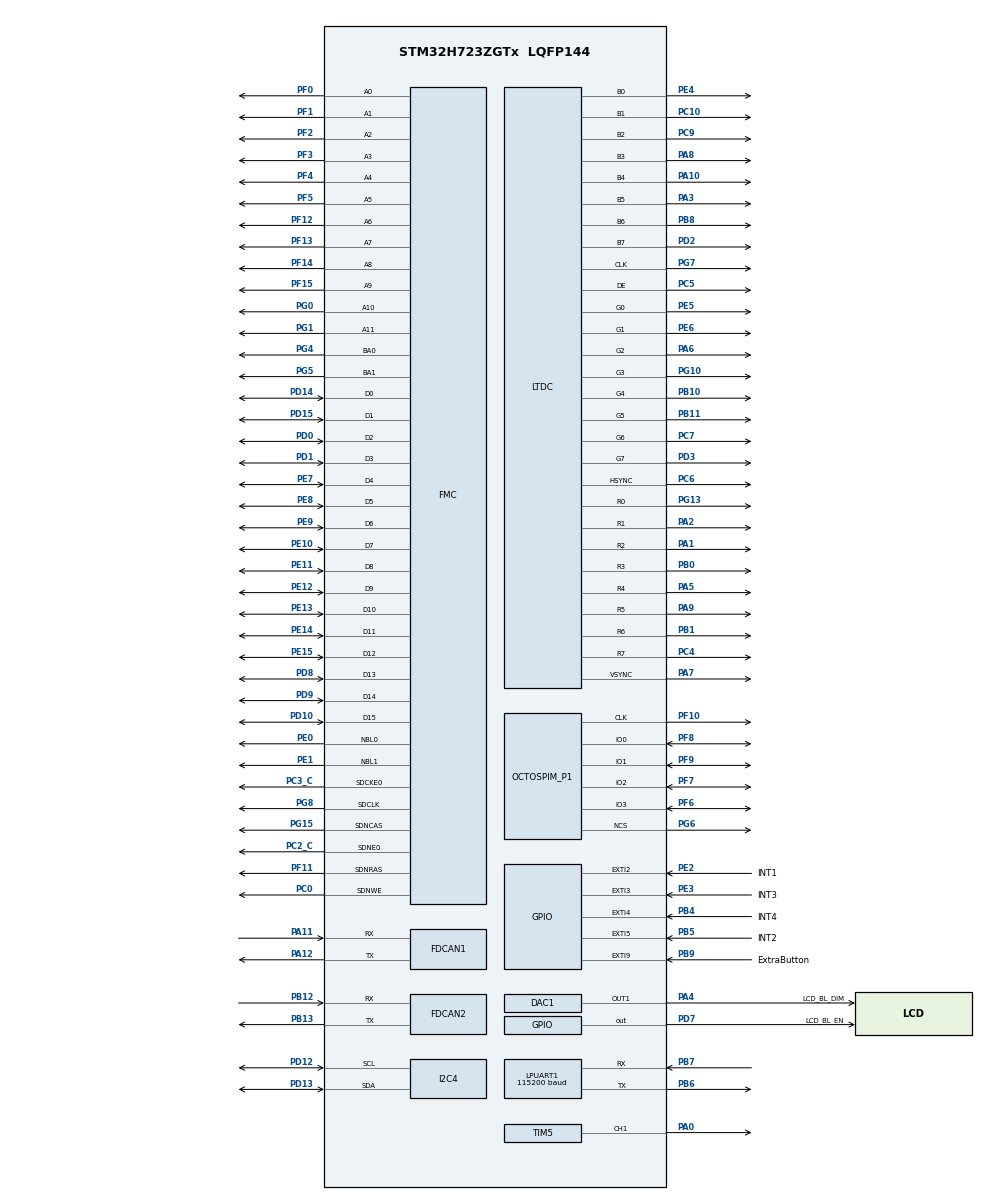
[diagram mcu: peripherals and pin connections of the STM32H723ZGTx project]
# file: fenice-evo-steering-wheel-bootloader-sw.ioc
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DAC1.DAC_Channel-DAC_OUT1=DAC_CHANNEL_1
DMA2D.ColorMode=DMA2D_OUTPUT_ARGB8888
FDCAN1.CalculateBaudRateNominal=1000000
FDCAN1.CalculateTimeBitNominal=1000
FDCAN1.CalculateTimeQuantumNominal=41.666666666666664
FDCAN1.DataPrescaler=1
FDCAN1.DataTimeSeg1=1
FDCAN1.NominalPrescaler=1
FDCAN1.NominalSyncJumpWidth=64
FDCAN1.NominalTimeSeg1=18
FDCAN1.NominalTimeSeg2=5
FDCAN1.RxFifo0ElmtsNbr=64
FDCAN1.RxFifo1ElmtsNbr=64
FDCAN1.StdFiltersNbr=1
FDCAN1.TxBuffersNbr=0
FDCAN1.TxEventsNbr=32
FDCAN1.TxFifoQueueElmtsNbr=32
FDCAN2.CalculateBaudRateNominal=1090909
FDCAN2.CalculateTimeBitNominal=916
FDCAN2.CalculateTimeQuantumNominal=83.33333333333333
FDCAN2.DataTimeSeg1=2
FDCAN2.NominalPrescaler=2
FDCAN2.NominalSyncJumpWidth=64
FDCAN2.NominalTimeSeg1=9
FDCAN2.RxFifo0ElmtsNbr=64
FDCAN2.RxFifo1ElmtsNbr=64
FDCAN2.StdFiltersNbr=1
FDCAN2.TxBuffersNbr=0
FDCAN2.TxEventsNbr=32
FDCAN2.TxFifoQueueElmtsNbr=32
FMC.BankMapConfig=FMC_SWAPBMAP_DISABLE
FMC.CASLatency1=FMC_SDRAM_CAS_LATENCY_3
FMC.ColumnBitsNumber1=FMC_SDRAM_COLUMN_BITS_NUM_8
FMC.ExitSelfRefreshDelay1=7
FMC.LoadToActiveDelay1=2
FMC.RCDDelay1=2
FMC.RPDelay1=2
FMC.ReadBurst1=FMC_SDRAM_RBURST_ENABLE
FMC.ReadPipeDelay1=FMC_SDRAM_RPIPE_DELAY_1
FMC.ReadPipeDelay2=FMC_SDRAM_RPIPE_DELAY_1
FMC.RowCycleDelay1=7
FMC.RowCycleDelay2=7
FMC.SDClockPeriod1=FMC_SDRAM_CLOCK_PERIOD_2
FMC.SelfRefreshTime1=5
FMC.WriteRecoveryTime1=3
LPUART1.BaudRate=115200
LPUART1.Mode=UART_MODE_TX_RX
LPUART1.SwapParam=UART_ADVFEATURE_SWAP_DISABLE
LTDC.ActiveW=800
LTDC.Alpha0_L0=0
LTDC.Alpha_L0=255
LTDC.Alpha_L1=255
LTDC.Blue_L0=0
LTDC.DEPolarity=LTDC_DEPOLARITY_AL
LTDC.FBStartAdress_L0=0xC0000000
LTDC.FBStartAdress_L1=0xC0177000
LTDC.HBP=20
LTDC.HFP=20
LTDC.HSPolarity=LTDC_HSPOLARITY_AL
LTDC.HSync=1
LTDC.ImageHeight_L0=480
LTDC.ImageHeight_L1=480
LTDC.ImageWidth_L0=800
LTDC.Layers=0
LTDC.PCPolarity=LTDC_PCPOLARITY_IPC
LTDC.PixelFormat_L0=LTDC_PIXEL_FORMAT_ARGB8888
LTDC.Red=0
LTDC.Red_L0=0
LTDC.VBP=20
LTDC.VFP=20
LTDC.VSPolarity=LTDC_VSPOLARITY_AL
LTDC.VSync=2
LTDC.WindowX0_L0=0
LTDC.WindowX1_L0=800
LTDC.WindowX1_L1=800
LTDC.WindowY0_L0=0
LTDC.WindowY1_L0=480
LTDC.WindowY1_L1=480
Mcu.Family=STM32H7
Mcu.Name=STM32H723ZGTx
Mcu.Package=LQFP144
NVIC.EXTI9_5_IRQn=true\:0\:0\:false\:false\:true\:true\:true\:true
NVIC.FDCAN1_IT0_IRQn=true\:0\:0\:false\:false\:true\:true\:true\:true
NVIC.FDCAN1_IT1_IRQn=true\:0\:0\:false\:false\:true\:true\:true\:true
NVIC.FDCAN2_IT0_IRQn=true\:0\:0\:false\:false\:true\:true\:true\:true
NVIC.FDCAN2_IT1_IRQn=true\:0\:0\:false\:false\:true\:true\:true\:true
NVIC.PriorityGroup=NVIC_PRIORITYGROUP_4
NVIC.TIM7_IRQn=true\:0\:0\:false\:false\:true\:true\:true\:true
PA0.Signal=S_TIM5_CH1
PA1.GPIO_Speed=GPIO_SPEED_FREQ_VERY_HIGH
PA1.Mode=RGB888
PA1.Signal=LTDC_R2
PA10.GPIO_Speed=GPIO_SPEED_FREQ_VERY_HIGH
PA10.Mode=RGB888
PA10.Signal=LTDC_B4
PA11.GPIO_Speed=GPIO_SPEED_FREQ_VERY_HIGH
PA11.Mode=FDCAN_Activate
PA11.Signal=FDCAN1_RX
PA12.GPIO_Speed=GPIO_SPEED_FREQ_VERY_HIGH
PA12.Mode=FDCAN_Activate
PA12.Signal=FDCAN1_TX
PA2.GPIO_Speed=GPIO_SPEED_FREQ_VERY_HIGH
PA2.Mode=RGB888
PA2.Signal=LTDC_R1
PA3.GPIO_Speed=GPIO_SPEED_FREQ_VERY_HIGH
PA3.Mode=RGB888
PA3.Signal=LTDC_B5
PA4.GPIO_Label=LCD_BL_DIM
PA4.Signal=COMP_DAC11_group
PA5.GPIO_Speed=GPIO_SPEED_FREQ_VERY_HIGH
PA5.Mode=RGB888
PA5.Signal=LTDC_R4
PA6.GPIO_Speed=GPIO_SPEED_FREQ_VERY_HIGH
PA6.Mode=RGB888
PA6.Signal=LTDC_G2
PA7.GPIO_Speed=GPIO_SPEED_FREQ_VERY_HIGH
PA7.Mode=RGB888
PA7.Signal=LTDC_VSYNC
PA8.GPIO_PuPd=GPIO_NOPULL
PA8.GPIO_Speed=GPIO_SPEED_FREQ_VERY_HIGH
PA8.Mode=RGB888
PA8.Signal=LTDC_B3
PA9.GPIO_Speed=GPIO_SPEED_FREQ_VERY_HIGH
PA9.Mode=RGB888
PA9.Signal=LTDC_R5
PB0.GPIO_Speed=GPIO_SPEED_FREQ_VERY_HIGH
PB0.Mode=RGB888
PB0.Signal=LTDC_R3
PB1.GPIO_Speed=GPIO_SPEED_FREQ_VERY_HIGH
PB1.Mode=RGB888
PB1.Signal=LTDC_R6
PB10.GPIO_Speed=GPIO_SPEED_FREQ_VERY_HIGH
PB10.Mode=RGB888
PB10.Signal=LTDC_G4
PB11.GPIO_Speed=GPIO_SPEED_FREQ_VERY_HIGH
PB11.Mode=RGB888
PB11.Signal=LTDC_G5
PB12.GPIO_Speed=GPIO_SPEED_FREQ_VERY_HIGH
PB12.Mode=FDCAN_Activate
PB12.Signal=FDCAN2_RX
PB13.GPIO_Speed=GPIO_SPEED_FREQ_VERY_HIGH
PB13.Mode=FDCAN_Activate
PB13.Signal=FDCAN2_TX
PB4(NJTRST).GPIO_Label=INT4
PB4(NJTRST).GPIO_PuPd=GPIO_NOPULL
PB4(NJTRST).Signal=GPXTI4
PB5.GPIO_Label=INT2
PB5.GPIO_PuPd=GPIO_NOPULL
PB5.Signal=GPXTI5
PB6.Mode=Asynchronous
PB6.Signal=LPUART1_TX
PB7.Mode=Asynchronous
PB7.Signal=LPUART1_RX
PB8.GPIO_Speed=GPIO_SPEED_FREQ_VERY_HIGH
PB8.Mode=RGB888
PB8.Signal=LTDC_B6
PB9.GPIO_Label=ExtraButton
PB9.GPIO_PuPd=GPIO_NOPULL
PB9.Signal=GPXTI9
PC0.GPIO_Speed_High_Default=GPIO_SPEED_FREQ_VERY_HIGH
PC0.Signal=FMC_SDNWE
PC10.GPIO_Speed=GPIO_SPEED_FREQ_VERY_HIGH
PC10.Mode=RGB888
PC10.Signal=LTDC_B1
PC2_C.GPIO_Speed_High_Default=GPIO_SPEED_FREQ_VERY_HIGH
PC2_C.Mode=SdramChipSelect1_1
PC2_C.Signal=FMC_SDNE0
PC3_C.GPIO_Speed_High_Default=GPIO_SPEED_FREQ_VERY_HIGH
PC3_C.Mode=SdramChipSelect1_1
PC3_C.Signal=FMC_SDCKE0
PC4.GPIO_Speed=GPIO_SPEED_FREQ_VERY_HIGH
PC4.Mode=RGB888
PC4.Signal=LTDC_R7
PC5.GPIO_Speed=GPIO_SPEED_FREQ_VERY_HIGH
PC5.Mode=RGB888
PC5.Signal=LTDC_DE
PC6.GPIO_Speed=GPIO_SPEED_FREQ_VERY_HIGH
PC6.Mode=RGB888
PC6.Signal=LTDC_HSYNC
PC7.GPIO_Speed=GPIO_SPEED_FREQ_VERY_HIGH
PC7.Mode=RGB888
PC7.Signal=LTDC_G6
PC9.GPIO_Speed=GPIO_SPEED_FREQ_VERY_HIGH
PC9.Mode=RGB888
PC9.Signal=LTDC_B2
PD0.GPIO_Speed_High_Default=GPIO_SPEED_FREQ_VERY_HIGH
PD0.Signal=FMC_D2_DA2
PD1.GPIO_Speed_High_Default=GPIO_SPEED_FREQ_VERY_HIGH
PD1.Signal=FMC_D3_DA3
PD10.GPIO_Speed_High_Default=GPIO_SPEED_FREQ_VERY_HIGH
PD10.Signal=FMC_D15_DA15
PD12.Mode=I2C
PD12.Signal=I2C4_SCL
PD13.Mode=I2C
PD13.Signal=I2C4_SDA
PD14.GPIO_Speed_High_Default=GPIO_SPEED_FREQ_VERY_HIGH
PD14.Signal=FMC_D0_DA0
PD15.GPIO_Speed_High_Default=GPIO_SPEED_FREQ_VERY_HIGH
PD15.Signal=FMC_D1_DA1
PD2.GPIO_Speed=GPIO_SPEED_FREQ_VERY_HIGH
PD2.Mode=RGB888
PD2.Signal=LTDC_B7
PD3.GPIO_Speed=GPIO_SPEED_FREQ_VERY_HIGH
PD3.Mode=RGB888
PD3.Signal=LTDC_G7
PD7.GPIO_Label=LCD_BL_EN
PD7.GPIO_PuPd=GPIO_NOPULL
PD7.Signal=GPIO_Output
PD8.GPIO_Speed_High_Default=GPIO_SPEED_FREQ_VERY_HIGH
PD8.Signal=FMC_D13_DA13
PD9.GPIO_Speed_High_Default=GPIO_SPEED_FREQ_VERY_HIGH
PD9.Signal=FMC_D14_DA14
PE0.Signal=FMC_NBL0
PE1.Signal=FMC_NBL1
PE10.GPIO_Speed_High_Default=GPIO_SPEED_FREQ_VERY_HIGH
PE10.Signal=FMC_D7_DA7
PE11.GPIO_Speed_High_Default=GPIO_SPEED_FREQ_VERY_HIGH
PE11.Signal=FMC_D8_DA8
PE12.GPIO_Speed_High_Default=GPIO_SPEED_FREQ_VERY_HIGH
PE12.Signal=FMC_D9_DA9
PE13.GPIO_Speed_High_Default=GPIO_SPEED_FREQ_VERY_HIGH
PE13.Signal=FMC_D10_DA10
PE14.GPIO_Speed_High_Default=GPIO_SPEED_FREQ_VERY_HIGH
PE14.Signal=FMC_D11_DA11
PE15.GPIO_Speed_High_Default=GPIO_SPEED_FREQ_VERY_HIGH
PE15.Signal=FMC_D12_DA12
PE2.GPIO_Label=INT1
PE2.GPIO_PuPd=GPIO_NOPULL
PE2.Signal=GPXTI2
PE3.GPIO_Label=INT3
PE3.GPIO_PuPd=GPIO_NOPULL
PE3.Signal=GPXTI3
PE4.GPIO_Speed=GPIO_SPEED_FREQ_VERY_HIGH
PE4.Mode=RGB888
PE4.Signal=LTDC_B0
PE5.GPIO_Speed=GPIO_SPEED_FREQ_VERY_HIGH
PE5.Mode=RGB888
PE5.Signal=LTDC_G0
PE6.GPIO_Speed=GPIO_SPEED_FREQ_VERY_HIGH
PE6.Mode=RGB888
PE6.Signal=LTDC_G1
PE7.GPIO_Speed_High_Default=GPIO_SPEED_FREQ_VERY_HIGH
PE7.Signal=FMC_D4_DA4
PE8.GPIO_Speed_High_Default=GPIO_SPEED_FREQ_VERY_HIGH
PE8.Signal=FMC_D5_DA5
PE9.GPIO_Speed_High_Default=GPIO_SPEED_FREQ_VERY_HIGH
PE9.Signal=FMC_D6_DA6
PF0.GPIO_Speed_High_Default=GPIO_SPEED_FREQ_VERY_HIGH
PF0.Signal=FMC_A0
PF1.GPIO_Speed_High_Default=GPIO_SPEED_FREQ_VERY_HIGH
PF1.Signal=FMC_A1
PF10.Mode=O1_P1_CLK
PF10.Signal=OCTOSPIM_P1_CLK
PF11.GPIO_Speed_High_Default=GPIO_SPEED_FREQ_VERY_HIGH
PF11.Signal=FMC_SDNRAS
PF12.GPIO_Speed_High_Default=GPIO_SPEED_FREQ_VERY_HIGH
PF12.Signal=FMC_A6
PF13.GPIO_Speed_High_Default=GPIO_SPEED_FREQ_VERY_HIGH
PF13.Signal=FMC_A7
PF14.GPIO_Speed_High_Default=GPIO_SPEED_FREQ_VERY_HIGH
PF14.Signal=FMC_A8
PF15.GPIO_Speed_High_Default=GPIO_SPEED_FREQ_VERY_HIGH
PF15.Signal=FMC_A9
PF2.GPIO_Speed_High_Default=GPIO_SPEED_FREQ_VERY_HIGH
PF2.Signal=FMC_A2
PF3.GPIO_Speed_High_Default=GPIO_SPEED_FREQ_VERY_HIGH
PF3.Signal=FMC_A3
PF4.GPIO_Speed_High_Default=GPIO_SPEED_FREQ_VERY_HIGH
PF4.Signal=FMC_A4
PF5.GPIO_Speed_High_Default=GPIO_SPEED_FREQ_VERY_HIGH
PF5.Signal=FMC_A5
PF6.Mode=OCTOSPI1_IOL_Port1L
PF6.Signal=OCTOSPIM_P1_IO3
PF7.Mode=OCTOSPI1_IOL_Port1L
PF7.Signal=OCTOSPIM_P1_IO2
PF8.Mode=OCTOSPI1_IOL_Port1L
PF8.Signal=OCTOSPIM_P1_IO0
PF9.Mode=OCTOSPI1_IOL_Port1L
PF9.Signal=OCTOSPIM_P1_IO1
PG0.GPIO_Speed_High_Default=GPIO_SPEED_FREQ_VERY_HIGH
PG0.Signal=FMC_A10
PG1.GPIO_Speed_High_Default=GPIO_SPEED_FREQ_VERY_HIGH
PG1.Signal=FMC_A11
PG10.GPIO_Speed=GPIO_SPEED_FREQ_VERY_HIGH
PG10.Mode=RGB888
PG10.Signal=LTDC_G3
PG13.GPIO_Speed=GPIO_SPEED_FREQ_VERY_HIGH
PG13.Mode=RGB888
PG13.Signal=LTDC_R0
PG15.GPIO_Speed_High_Default=GPIO_SPEED_FREQ_VERY_HIGH
PG15.Signal=FMC_SDNCAS
PG4.GPIO_Speed_High_Default=GPIO_SPEED_FREQ_VERY_HIGH
PG4.Signal=FMC_A14_BA0
PG5.GPIO_Speed_High_Default=GPIO_SPEED_FREQ_VERY_HIGH
PG5.Signal=FMC_A15_BA1
PG6.Mode=OCTOSPI1_Port1_NCS
PG6.Signal=OCTOSPIM_P1_NCS
PG7.GPIO_Speed=GPIO_SPEED_FREQ_VERY_HIGH
PG7.Mode=RGB888
PG7.Signal=LTDC_CLK
PG8.GPIO_Speed_High_Default=GPIO_SPEED_FREQ_VERY_HIGH
PG8.Signal=FMC_SDCLK
PH0-OSC_IN.Mode=HSE-External-Oscillator
PH0-OSC_IN.Signal=RCC_OSC_IN
PH1-OSC_OUT.Mode=HSE-External-Oscillator
PH1-OSC_OUT.Signal=RCC_OSC_OUT
ProjectManager.HeapSize=0x200
ProjectManager.StackSize=0x400
ProjectManager.TargetToolchain=Makefile
RCC.ADCFreq_Value=300000000
RCC.APB1Freq_Value=137500000
RCC.APB2Freq_Value=137500000
RCC.APB3Freq_Value=137500000
RCC.APB4Freq_Value=137500000
RCC.CKPERSourceSelection=RCC_CLKPSOURCE_HSE
RCC.CortexFreq_Value=550000000
RCC.D1PPRE=RCC_APB3_DIV2
RCC.D2PPRE1=RCC_APB1_DIV2
RCC.D2PPRE2=RCC_APB2_DIV2
RCC.D3PPRE=RCC_APB4_DIV2
RCC.DIVM1=6
RCC.DIVM2=2
RCC.DIVM3=2
RCC.DIVN1=137
RCC.DIVN2=50
RCC.DIVN3=50
RCC.DIVP1=1
RCC.DIVQ1=5
RCC.DIVQ2=4
RCC.DIVQ3=4
RCC.DIVR2=3
RCC.DIVR3=24
RCC.FDCANCLockSelection=RCC_FDCANCLKSOURCE_HSE
RCC.FMCCLockSelection=RCC_FMCCLKSOURCE_PLL2
RCC.HCLKFreq_Value=275000000
RCC.HPRE=RCC_HCLK_DIV2
RCC.HSE_VALUE=24000000
RCC.I2C4CLockSelection=RCC_I2C4CLKSOURCE_HSI
RCC.LPUART1CLockSelection=RCC_LPUART1CLKSOURCE_CSI
RCC.PLL2FRACN=0
RCC.PLL3FRACN=0
RCC.PLLFRACN=4096
RCC.PLLSourceVirtual=RCC_PLLSOURCE_HSE
RCC.QSPICLockSelection=RCC_OSPICLKSOURCE_PLL
RCC.SYSCLKFreq_VALUE=550000000
RCC.SYSCLKSource=RCC_SYSCLKSOURCE_PLLCLK
RCC.USBFreq_Value=110000000
SH.COMP_DAC11_group.0=DAC1_OUT1,DAC_OUT1
SH.FMC_A0.0=FMC_A0,12b-sda1
SH.FMC_A1.0=FMC_A1,12b-sda1
SH.FMC_A10.0=FMC_A10,12b-sda1
SH.FMC_A11.0=FMC_A11,12b-sda1
SH.FMC_A14_BA0.0=FMC_BA0,FourSdramBanks1
SH.FMC_A15_BA1.0=FMC_BA1,FourSdramBanks1
SH.FMC_A2.0=FMC_A2,12b-sda1
SH.FMC_A3.0=FMC_A3,12b-sda1
SH.FMC_A4.0=FMC_A4,12b-sda1
SH.FMC_A5.0=FMC_A5,12b-sda1
SH.FMC_A6.0=FMC_A6,12b-sda1
SH.FMC_A7.0=FMC_A7,12b-sda1
SH.FMC_A8.0=FMC_A8,12b-sda1
SH.FMC_A9.0=FMC_A9,12b-sda1
SH.FMC_D0_DA0.0=FMC_D0,sd-16b-d1
SH.FMC_D10_DA10.0=FMC_D10,sd-16b-d1
SH.FMC_D11_DA11.0=FMC_D11,sd-16b-d1
SH.FMC_D12_DA12.0=FMC_D12,sd-16b-d1
SH.FMC_D13_DA13.0=FMC_D13,sd-16b-d1
SH.FMC_D14_DA14.0=FMC_D14,sd-16b-d1
SH.FMC_D15_DA15.0=FMC_D15,sd-16b-d1
SH.FMC_D1_DA1.0=FMC_D1,sd-16b-d1
SH.FMC_D2_DA2.0=FMC_D2,sd-16b-d1
SH.FMC_D3_DA3.0=FMC_D3,sd-16b-d1
SH.FMC_D4_DA4.0=FMC_D4,sd-16b-d1
SH.FMC_D5_DA5.0=FMC_D5,sd-16b-d1
SH.FMC_D6_DA6.0=FMC_D6,sd-16b-d1
SH.FMC_D7_DA7.0=FMC_D7,sd-16b-d1
SH.FMC_D8_DA8.0=FMC_D8,sd-16b-d1
SH.FMC_D9_DA9.0=FMC_D9,sd-16b-d1
SH.FMC_NBL0.0=FMC_NBL0,Sd2ByteEnable1
SH.FMC_NBL1.0=FMC_NBL1,Sd2ByteEnable1
SH.FMC_SDCLK.0=FMC_SDCLK,12b-sda1
SH.FMC_SDNCAS.0=FMC_SDNCAS,12b-sda1
SH.FMC_SDNRAS.0=FMC_SDNRAS,12b-sda1
SH.FMC_SDNWE.0=FMC_SDNWE,12b-sda1
SH.S_TIM5_CH1.0=TIM5_CH1,PWM Generation1 CH1
TIM5.Channel-PWM\ Generation1\ CH1=TIM_CHANNEL_1
TIM7.Period=10000
TIM7.Prescaler=8000
TIM7.TIM_MasterOutputTrigger=TIM_TRGO_RESET
VP_DMA2D_VS_DMA2D.Mode=DMA2D_Activate
VP_OCTOSPI1_VS_quad.Mode=quad_mode
VP_TIM5_VS_ClockSourceINT.Mode=Internal
VP_TIM7_VS_ClockSourceINT.Mode=Enable_Timer
board=custom

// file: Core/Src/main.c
/* USER CODE BEGIN Header */
/**
  ******************************************************************************
  * @file           : main.c
  * @brief          : Main program body
  ******************************************************************************
  * @attention
  *
  * Copyright (c) 2023 STMicroelectronics.
  * All rights reserved.
  *
  * This software is licensed under terms that can be found in the LICENSE file
  * in the root directory of this software component.
  * If no LICENSE file comes with this software, it is provided AS-IS.
  *
  ******************************************************************************
  */
/* USER CODE END Header */
#include "main.h"
#include "dac.h"
#include "dma2d.h"
#include "fdcan.h"
#include "i2c.h"
#include "usart.h"
#include "ltdc.h"
#include "octospi.h"
#include "tim.h"
#include "gpio.h"
#include "fmc.h"

/* USER CODE BEGIN Includes */

#include "bootloader-screen.h"

/* USER CODE END Includes */

void SystemClock_Config(void);

int main(void) {

    /* MCU Configuration--------------------------------------------------------*/

    /* Reset of all peripherals, Initializes the Flash interface and the Systick. */
    HAL_Init();

    /* Configure the system clock */
    SystemClock_Config();

    /* USER CODE BEGIN SysInit */

    // VectorBase_Config();

    /* OpenBLT's millisecond timer (TIM1, polled) is also the HAL tick
   * (HAL_GetTick is overridden in timer.c): start it now, BootInit() would be
   * too late for the HAL_Delay() and the SDRAM init below.
   */
    TimerInit();

    /* USER CODE END SysInit */

    /* Initialize all configured peripherals */
    MX_GPIO_Init();
    MX_FDCAN1_Init();
    MX_FDCAN2_Init();
    MX_FMC_Init();
    MX_LPUART1_UART_Init();
    MX_LTDC_Init();
    MX_OCTOSPI1_Init();
    MX_I2C4_Init();
    MX_TIM5_Init();
    MX_DAC1_Init();
    MX_TIM7_Init();
    MX_DMA2D_Init();
    /* USER CODE BEGIN 2 */

    /* Logo first, backlight after: the SDRAM holds random data at power-up. */
    (void)bootloader_screen_init();

    HAL_GPIO_WritePin(LCD_BL_EN_GPIO_Port, LCD_BL_EN_Pin, GPIO_PIN_SET);
    HAL_DAC_SetValue(&hdac1, DAC_CHANNEL_1, DAC_ALIGN_12B_R, 0);
    HAL_Delay(100);

    BootInit();

    /* USER CODE END 2 */

    /* Infinite loop */
    while (1) {

        /* USER CODE BEGIN 3 */
        BootTask();
        /* "FLASHING STEERING WHEEL" while a flashing tool is connected, logo only otherwise. */
        bootloader_screen_update(ComIsConnected() == BLT_TRUE);
    }
    /* USER CODE END 3 */
}

void SystemClock_Config(void) {
    RCC_OscInitTypeDef RCC_OscInitStruct = { 0 };
    RCC_ClkInitTypeDef RCC_ClkInitStruct = { 0 };

    /** Supply configuration update enable
  */
    HAL_PWREx_ConfigSupply(PWR_LDO_SUPPLY);

    /** Configure the main internal regulator output voltage
  */
    __HAL_PWR_VOLTAGESCALING_CONFIG(PWR_REGULATOR_VOLTAGE_SCALE0);

    while (!__HAL_PWR_GET_FLAG(PWR_FLAG_VOSRDY)) {
    }

    /** Initializes the RCC Oscillators according to the specified parameters
  * in the RCC_OscInitTypeDef structure.
  */
    RCC_OscInitStruct.OscillatorType = RCC_OSCILLATORTYPE_CSI | RCC_OSCILLATORTYPE_HSI | RCC_OSCILLATORTYPE_HSE;
    RCC_OscInitStruct.HSEState = RCC_HSE_ON;
    RCC_OscInitStruct.HSIState = RCC_HSI_DIV1;
    RCC_OscInitStruct.HSICalibrationValue = 64;
    RCC_OscInitStruct.CSIState = RCC_CSI_ON;
    RCC_OscInitStruct.CSICalibrationValue = 16;
    RCC_OscInitStruct.PLL.PLLState = RCC_PLL_ON;
    RCC_OscInitStruct.PLL.PLLSource = RCC_PLLSOURCE_HSE;
    RCC_OscInitStruct.PLL.PLLM = 6;
    RCC_OscInitStruct.PLL.PLLN = 137;
    RCC_OscInitStruct.PLL.PLLP = 1;
    RCC_OscInitStruct.PLL.PLLQ = 5;
    RCC_OscInitStruct.PLL.PLLR = 2;
    RCC_OscInitStruct.PLL.PLLRGE = RCC_PLL1VCIRANGE_2;
    RCC_OscInitStruct.PLL.PLLVCOSEL = RCC_PLL1VCOWIDE;
    RCC_OscInitStruct.PLL.PLLFRACN = 4096;
    if (HAL_RCC_OscConfig(&RCC_OscInitStruct) != HAL_OK) {
        Error_Handler();
    }

    /** Initializes the CPU, AHB and APB buses clocks
  */
    RCC_ClkInitStruct.ClockType = RCC_CLOCKTYPE_HCLK | RCC_CLOCKTYPE_SYSCLK | RCC_CLOCKTYPE_PCLK1 | RCC_CLOCKTYPE_PCLK2 | RCC_CLOCKTYPE_D3PCLK1 | RCC_CLOCKTYPE_D1PCLK1;
    RCC_ClkInitStruct.SYSCLKSource = RCC_SYSCLKSOURCE_PLLCLK;
    RCC_ClkInitStruct.SYSCLKDivider = RCC_SYSCLK_DIV1;
    RCC_ClkInitStruct.AHBCLKDivider = RCC_HCLK_DIV2;
    RCC_ClkInitStruct.APB3CLKDivider = RCC_APB3_DIV2;
    RCC_ClkInitStruct.APB1CLKDivider = RCC_APB1_DIV2;
    RCC_ClkInitStruct.APB2CLKDivider = RCC_APB2_DIV2;
    RCC_ClkInitStruct.APB4CLKDivider = RCC_APB4_DIV2;

    if (HAL_RCC_ClockConfig(&RCC_ClkInitStruct, FLASH_LATENCY_3) != HAL_OK) {
        Error_Handler();
    }
}

void Error_Handler(void) {
    __disable_irq();
    while (1) {
    }
}
